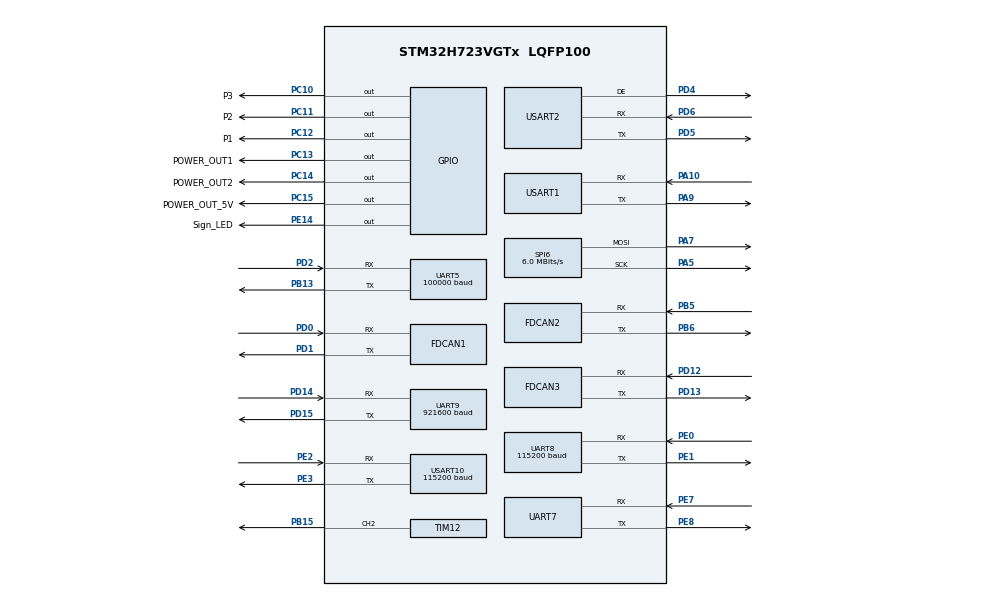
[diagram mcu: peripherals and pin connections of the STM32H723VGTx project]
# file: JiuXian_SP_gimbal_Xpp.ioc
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Bdma.Request0=SPI6_TX
Bdma.RequestsNb=1
Bdma.SPI6_TX.0.Direction=DMA_MEMORY_TO_PERIPH
Bdma.SPI6_TX.0.EventEnable=DISABLE
Bdma.SPI6_TX.0.Instance=BDMA_Channel0
Bdma.SPI6_TX.0.MemDataAlignment=DMA_MDATAALIGN_BYTE
Bdma.SPI6_TX.0.MemInc=DMA_MINC_ENABLE
Bdma.SPI6_TX.0.Mode=DMA_NORMAL
Bdma.SPI6_TX.0.PeriphDataAlignment=DMA_PDATAALIGN_BYTE
Bdma.SPI6_TX.0.PeriphInc=DMA_PINC_DISABLE
Bdma.SPI6_TX.0.Polarity=HAL_DMAMUX_REQ_GEN_RISING
Bdma.SPI6_TX.0.Priority=DMA_PRIORITY_LOW
Bdma.SPI6_TX.0.RequestNumber=1
Bdma.SPI6_TX.0.SignalID=NONE
Bdma.SPI6_TX.0.SyncEnable=DISABLE
Bdma.SPI6_TX.0.SyncPolarity=HAL_DMAMUX_SYNC_NO_EVENT
Bdma.SPI6_TX.0.SyncRequestNumber=1
Bdma.SPI6_TX.0.SyncSignalID=NONE
Dma.Request0=UART8_RX
Dma.Request1=UART8_TX
Dma.Request10=USART2_TX
Dma.Request11=USART10_RX
Dma.Request12=USART10_TX
Dma.Request2=UART9_RX
Dma.Request3=UART9_TX
Dma.Request4=USART1_RX
Dma.Request5=USART1_TX
Dma.Request6=UART7_RX
Dma.Request7=UART7_TX
Dma.Request8=UART5_RX
Dma.Request9=USART2_RX
Dma.UART5_RX.8.Direction=DMA_PERIPH_TO_MEMORY
Dma.UART5_RX.8.EventEnable=DISABLE
Dma.UART5_RX.8.FIFOMode=DMA_FIFOMODE_DISABLE
Dma.UART5_RX.8.Instance=DMA1_Stream0
Dma.UART5_RX.8.MemDataAlignment=DMA_MDATAALIGN_BYTE
Dma.UART5_RX.8.MemInc=DMA_MINC_ENABLE
Dma.UART5_RX.8.Mode=DMA_NORMAL
Dma.UART5_RX.8.PeriphDataAlignment=DMA_PDATAALIGN_BYTE
Dma.UART5_RX.8.PeriphInc=DMA_PINC_DISABLE
Dma.UART5_RX.8.Polarity=HAL_DMAMUX_REQ_GEN_RISING
Dma.UART5_RX.8.Priority=DMA_PRIORITY_HIGH
Dma.UART5_RX.8.RequestNumber=1
Dma.UART5_RX.8.SignalID=NONE
Dma.UART5_RX.8.SyncEnable=DISABLE
Dma.UART5_RX.8.SyncPolarity=HAL_DMAMUX_SYNC_NO_EVENT
Dma.UART5_RX.8.SyncRequestNumber=1
Dma.UART5_RX.8.SyncSignalID=NONE
Dma.UART7_RX.6.Direction=DMA_PERIPH_TO_MEMORY
Dma.UART7_RX.6.EventEnable=DISABLE
Dma.UART7_RX.6.FIFOMode=DMA_FIFOMODE_DISABLE
Dma.UART7_RX.6.Instance=DMA1_Stream6
Dma.UART7_RX.6.MemDataAlignment=DMA_MDATAALIGN_BYTE
Dma.UART7_RX.6.MemInc=DMA_MINC_ENABLE
Dma.UART7_RX.6.Mode=DMA_NORMAL
Dma.UART7_RX.6.PeriphDataAlignment=DMA_PDATAALIGN_BYTE
Dma.UART7_RX.6.PeriphInc=DMA_PINC_DISABLE
Dma.UART7_RX.6.Polarity=HAL_DMAMUX_REQ_GEN_RISING
Dma.UART7_RX.6.Priority=DMA_PRIORITY_LOW
Dma.UART7_RX.6.RequestNumber=1
Dma.UART7_RX.6.SignalID=NONE
Dma.UART7_RX.6.SyncEnable=DISABLE
Dma.UART7_RX.6.SyncPolarity=HAL_DMAMUX_SYNC_NO_EVENT
Dma.UART7_RX.6.SyncRequestNumber=1
Dma.UART7_RX.6.SyncSignalID=NONE
Dma.UART7_TX.7.Direction=DMA_MEMORY_TO_PERIPH
Dma.UART7_TX.7.EventEnable=DISABLE
Dma.UART7_TX.7.FIFOMode=DMA_FIFOMODE_DISABLE
Dma.UART7_TX.7.Instance=DMA1_Stream7
Dma.UART7_TX.7.MemDataAlignment=DMA_MDATAALIGN_BYTE
Dma.UART7_TX.7.MemInc=DMA_MINC_ENABLE
Dma.UART7_TX.7.Mode=DMA_NORMAL
Dma.UART7_TX.7.PeriphDataAlignment=DMA_PDATAALIGN_BYTE
Dma.UART7_TX.7.PeriphInc=DMA_PINC_DISABLE
Dma.UART7_TX.7.Polarity=HAL_DMAMUX_REQ_GEN_RISING
Dma.UART7_TX.7.Priority=DMA_PRIORITY_LOW
Dma.UART7_TX.7.RequestNumber=1
Dma.UART7_TX.7.SignalID=NONE
Dma.UART7_TX.7.SyncEnable=DISABLE
Dma.UART7_TX.7.SyncPolarity=HAL_DMAMUX_SYNC_NO_EVENT
Dma.UART7_TX.7.SyncRequestNumber=1
Dma.UART7_TX.7.SyncSignalID=NONE
Dma.UART8_RX.0.Direction=DMA_PERIPH_TO_MEMORY
Dma.UART8_RX.0.EventEnable=DISABLE
Dma.UART8_RX.0.FIFOMode=DMA_FIFOMODE_DISABLE
Dma.UART8_RX.0.Instance=DMA2_Stream0
Dma.UART8_RX.0.MemDataAlignment=DMA_MDATAALIGN_BYTE
Dma.UART8_RX.0.MemInc=DMA_MINC_ENABLE
Dma.UART8_RX.0.Mode=DMA_NORMAL
Dma.UART8_RX.0.PeriphDataAlignment=DMA_PDATAALIGN_BYTE
Dma.UART8_RX.0.PeriphInc=DMA_PINC_DISABLE
Dma.UART8_RX.0.Polarity=HAL_DMAMUX_REQ_GEN_RISING
Dma.UART8_RX.0.Priority=DMA_PRIORITY_LOW
Dma.UART8_RX.0.RequestNumber=1
Dma.UART8_RX.0.SignalID=NONE
Dma.UART8_RX.0.SyncEnable=DISABLE
Dma.UART8_RX.0.SyncPolarity=HAL_DMAMUX_SYNC_NO_EVENT
Dma.UART8_RX.0.SyncRequestNumber=1
Dma.UART8_RX.0.SyncSignalID=NONE
Dma.UART8_TX.1.Direction=DMA_MEMORY_TO_PERIPH
Dma.UART8_TX.1.EventEnable=DISABLE
Dma.UART8_TX.1.FIFOMode=DMA_FIFOMODE_DISABLE
Dma.UART8_TX.1.Instance=DMA1_Stream1
Dma.UART8_TX.1.MemDataAlignment=DMA_MDATAALIGN_BYTE
Dma.UART8_TX.1.MemInc=DMA_MINC_ENABLE
Dma.UART8_TX.1.Mode=DMA_NORMAL
Dma.UART8_TX.1.PeriphDataAlignment=DMA_PDATAALIGN_BYTE
Dma.UART8_TX.1.PeriphInc=DMA_PINC_DISABLE
Dma.UART8_TX.1.Polarity=HAL_DMAMUX_REQ_GEN_RISING
Dma.UART8_TX.1.Priority=DMA_PRIORITY_LOW
Dma.UART8_TX.1.RequestNumber=1
Dma.UART8_TX.1.SignalID=NONE
Dma.UART8_TX.1.SyncEnable=DISABLE
Dma.UART8_TX.1.SyncPolarity=HAL_DMAMUX_SYNC_NO_EVENT
Dma.UART8_TX.1.SyncRequestNumber=1
Dma.UART8_TX.1.SyncSignalID=NONE
Dma.UART9_RX.2.Direction=DMA_PERIPH_TO_MEMORY
Dma.UART9_RX.2.EventEnable=DISABLE
Dma.UART9_RX.2.FIFOMode=DMA_FIFOMODE_DISABLE
Dma.UART9_RX.2.Instance=DMA1_Stream2
Dma.UART9_RX.2.MemDataAlignment=DMA_MDATAALIGN_BYTE
Dma.UART9_RX.2.MemInc=DMA_MINC_ENABLE
Dma.UART9_RX.2.Mode=DMA_NORMAL
Dma.UART9_RX.2.PeriphDataAlignment=DMA_PDATAALIGN_BYTE
Dma.UART9_RX.2.PeriphInc=DMA_PINC_DISABLE
Dma.UART9_RX.2.Polarity=HAL_DMAMUX_REQ_GEN_RISING
Dma.UART9_RX.2.Priority=DMA_PRIORITY_LOW
Dma.UART9_RX.2.RequestNumber=1
Dma.UART9_RX.2.SignalID=NONE
Dma.UART9_RX.2.SyncEnable=DISABLE
Dma.UART9_RX.2.SyncPolarity=HAL_DMAMUX_SYNC_NO_EVENT
Dma.UART9_RX.2.SyncRequestNumber=1
Dma.UART9_RX.2.SyncSignalID=NONE
Dma.UART9_TX.3.Direction=DMA_MEMORY_TO_PERIPH
Dma.UART9_TX.3.EventEnable=DISABLE
Dma.UART9_TX.3.FIFOMode=DMA_FIFOMODE_DISABLE
Dma.UART9_TX.3.Instance=DMA1_Stream3
Dma.UART9_TX.3.MemDataAlignment=DMA_MDATAALIGN_BYTE
Dma.UART9_TX.3.MemInc=DMA_MINC_ENABLE
Dma.UART9_TX.3.Mode=DMA_NORMAL
Dma.UART9_TX.3.PeriphDataAlignment=DMA_PDATAALIGN_BYTE
Dma.UART9_TX.3.PeriphInc=DMA_PINC_DISABLE
Dma.UART9_TX.3.Polarity=HAL_DMAMUX_REQ_GEN_RISING
Dma.UART9_TX.3.Priority=DMA_PRIORITY_LOW
Dma.UART9_TX.3.RequestNumber=1
Dma.UART9_TX.3.SignalID=NONE
Dma.UART9_TX.3.SyncEnable=DISABLE
Dma.UART9_TX.3.SyncPolarity=HAL_DMAMUX_SYNC_NO_EVENT
Dma.UART9_TX.3.SyncRequestNumber=1
Dma.UART9_TX.3.SyncSignalID=NONE
Dma.USART10_RX.11.Direction=DMA_PERIPH_TO_MEMORY
Dma.USART10_RX.11.EventEnable=DISABLE
Dma.USART10_RX.11.FIFOMode=DMA_FIFOMODE_DISABLE
Dma.USART10_RX.11.Instance=DMA2_Stream3
Dma.USART10_RX.11.MemDataAlignment=DMA_MDATAALIGN_BYTE
Dma.USART10_RX.11.MemInc=DMA_MINC_ENABLE
Dma.USART10_RX.11.Mode=DMA_NORMAL
Dma.USART10_RX.11.PeriphDataAlignment=DMA_PDATAALIGN_BYTE
Dma.USART10_RX.11.PeriphInc=DMA_PINC_DISABLE
Dma.USART10_RX.11.Polarity=HAL_DMAMUX_REQ_GEN_RISING
Dma.USART10_RX.11.Priority=DMA_PRIORITY_LOW
Dma.USART10_RX.11.RequestNumber=1
Dma.USART10_RX.11.SignalID=NONE
Dma.USART10_RX.11.SyncEnable=DISABLE
Dma.USART10_RX.11.SyncPolarity=HAL_DMAMUX_SYNC_NO_EVENT
Dma.USART10_RX.11.SyncRequestNumber=1
Dma.USART10_RX.11.SyncSignalID=NONE
Dma.USART10_TX.12.Direction=DMA_MEMORY_TO_PERIPH
Dma.USART10_TX.12.EventEnable=DISABLE
Dma.USART10_TX.12.FIFOMode=DMA_FIFOMODE_DISABLE
Dma.USART10_TX.12.Instance=DMA2_Stream4
Dma.USART10_TX.12.MemDataAlignment=DMA_MDATAALIGN_BYTE
Dma.USART10_TX.12.MemInc=DMA_MINC_ENABLE
Dma.USART10_TX.12.Mode=DMA_NORMAL
Dma.USART10_TX.12.PeriphDataAlignment=DMA_PDATAALIGN_BYTE
Dma.USART10_TX.12.PeriphInc=DMA_PINC_DISABLE
Dma.USART10_TX.12.Polarity=HAL_DMAMUX_REQ_GEN_RISING
Dma.USART10_TX.12.Priority=DMA_PRIORITY_LOW
Dma.USART10_TX.12.RequestNumber=1
Dma.USART10_TX.12.SignalID=NONE
Dma.USART10_TX.12.SyncEnable=DISABLE
Dma.USART10_TX.12.SyncPolarity=HAL_DMAMUX_SYNC_NO_EVENT
Dma.USART10_TX.12.SyncRequestNumber=1
Dma.USART10_TX.12.SyncSignalID=NONE
Dma.USART1_RX.4.Direction=DMA_PERIPH_TO_MEMORY
Dma.USART1_RX.4.EventEnable=DISABLE
Dma.USART1_RX.4.FIFOMode=DMA_FIFOMODE_DISABLE
Dma.USART1_RX.4.Instance=DMA1_Stream4
Dma.USART1_RX.4.MemDataAlignment=DMA_MDATAALIGN_BYTE
Dma.USART1_RX.4.MemInc=DMA_MINC_ENABLE
Dma.USART1_RX.4.Mode=DMA_NORMAL
Dma.USART1_RX.4.PeriphDataAlignment=DMA_PDATAALIGN_BYTE
Dma.USART1_RX.4.PeriphInc=DMA_PINC_DISABLE
Dma.USART1_RX.4.Polarity=HAL_DMAMUX_REQ_GEN_RISING
Dma.USART1_RX.4.Priority=DMA_PRIORITY_LOW
Dma.USART1_RX.4.RequestNumber=1
Dma.USART1_RX.4.SignalID=NONE
Dma.USART1_RX.4.SyncEnable=DISABLE
Dma.USART1_RX.4.SyncPolarity=HAL_DMAMUX_SYNC_NO_EVENT
Dma.USART1_RX.4.SyncRequestNumber=1
Dma.USART1_RX.4.SyncSignalID=NONE
Dma.USART1_TX.5.Direction=DMA_MEMORY_TO_PERIPH
Dma.USART1_TX.5.EventEnable=DISABLE
Dma.USART1_TX.5.FIFOMode=DMA_FIFOMODE_DISABLE
Dma.USART1_TX.5.Instance=DMA1_Stream5
Dma.USART1_TX.5.MemDataAlignment=DMA_MDATAALIGN_BYTE
Dma.USART1_TX.5.MemInc=DMA_MINC_ENABLE
Dma.USART1_TX.5.Mode=DMA_NORMAL
Dma.USART1_TX.5.PeriphDataAlignment=DMA_PDATAALIGN_BYTE
Dma.USART1_TX.5.PeriphInc=DMA_PINC_DISABLE
Dma.USART1_TX.5.Polarity=HAL_DMAMUX_REQ_GEN_RISING
Dma.USART1_TX.5.Priority=DMA_PRIORITY_LOW
Dma.USART1_TX.5.RequestNumber=1
Dma.USART1_TX.5.SignalID=NONE
Dma.USART1_TX.5.SyncEnable=DISABLE
Dma.USART1_TX.5.SyncPolarity=HAL_DMAMUX_SYNC_NO_EVENT
Dma.USART1_TX.5.SyncRequestNumber=1
Dma.USART1_TX.5.SyncSignalID=NONE
Dma.USART2_RX.9.Direction=DMA_PERIPH_TO_MEMORY
Dma.USART2_RX.9.EventEnable=DISABLE
Dma.USART2_RX.9.FIFOMode=DMA_FIFOMODE_DISABLE
Dma.USART2_RX.9.Instance=DMA2_Stream1
Dma.USART2_RX.9.MemDataAlignment=DMA_MDATAALIGN_BYTE
Dma.USART2_RX.9.MemInc=DMA_MINC_ENABLE
Dma.USART2_RX.9.Mode=DMA_NORMAL
Dma.USART2_RX.9.PeriphDataAlignment=DMA_PDATAALIGN_BYTE
Dma.USART2_RX.9.PeriphInc=DMA_PINC_DISABLE
Dma.USART2_RX.9.Polarity=HAL_DMAMUX_REQ_GEN_RISING
Dma.USART2_RX.9.Priority=DMA_PRIORITY_LOW
Dma.USART2_RX.9.RequestNumber=1
Dma.USART2_RX.9.SignalID=NONE
Dma.USART2_RX.9.SyncEnable=DISABLE
Dma.USART2_RX.9.SyncPolarity=HAL_DMAMUX_SYNC_NO_EVENT
Dma.USART2_RX.9.SyncRequestNumber=1
Dma.USART2_RX.9.SyncSignalID=NONE
Dma.USART2_TX.10.Direction=DMA_MEMORY_TO_PERIPH
Dma.USART2_TX.10.EventEnable=DISABLE
Dma.USART2_TX.10.FIFOMode=DMA_FIFOMODE_DISABLE
Dma.USART2_TX.10.Instance=DMA2_Stream2
Dma.USART2_TX.10.MemDataAlignment=DMA_MDATAALIGN_BYTE
Dma.USART2_TX.10.MemInc=DMA_MINC_ENABLE
Dma.USART2_TX.10.Mode=DMA_NORMAL
Dma.USART2_TX.10.PeriphDataAlignment=DMA_PDATAALIGN_BYTE
Dma.USART2_TX.10.PeriphInc=DMA_PINC_DISABLE
Dma.USART2_TX.10.Polarity=HAL_DMAMUX_REQ_GEN_RISING
Dma.USART2_TX.10.Priority=DMA_PRIORITY_LOW
Dma.USART2_TX.10.RequestNumber=1
Dma.USART2_TX.10.SignalID=NONE
Dma.USART2_TX.10.SyncEnable=DISABLE
Dma.USART2_TX.10.SyncPolarity=HAL_DMAMUX_SYNC_NO_EVENT
Dma.USART2_TX.10.SyncRequestNumber=1
Dma.USART2_TX.10.SyncSignalID=NONE
FDCAN1.AutoRetransmission=ENABLE
FDCAN1.CalculateBaudRateNominal=1000000
FDCAN1.CalculateTimeBitNominal=1000
FDCAN1.CalculateTimeQuantumNominal=25.0
FDCAN1.DataPrescaler=3
FDCAN1.DataSyncJumpWidth=10
FDCAN1.DataTimeSeg1=29
FDCAN1.DataTimeSeg2=10
FDCAN1.NominalPrescaler=3
FDCAN1.NominalSyncJumpWidth=10
FDCAN1.NominalTimeSeg1=29
FDCAN1.NominalTimeSeg2=10
FDCAN1.RxFifo0ElmtsNbr=16
FDCAN1.StdFiltersNbr=1
FDCAN1.TxFifoQueueElmtsNbr=8
FDCAN2.AutoRetransmission=ENABLE
FDCAN2.CalculateBaudRateNominal=1000000
FDCAN2.CalculateTimeBitNominal=1000
FDCAN2.CalculateTimeQuantumNominal=25.0
FDCAN2.DataPrescaler=3
FDCAN2.DataSyncJumpWidth=2
FDCAN2.DataTimeSeg1=5
FDCAN2.DataTimeSeg2=2
FDCAN2.FrameFormat=FDCAN_FRAME_FD_BRS
FDCAN2.MessageRAMOffset=853
FDCAN2.Mode=FDCAN_MODE_NORMAL
FDCAN2.NominalPrescaler=3
FDCAN2.NominalSyncJumpWidth=10
FDCAN2.NominalTimeSeg1=29
FDCAN2.NominalTimeSeg2=10
FDCAN2.RxFifo0ElmtSize=FDCAN_DATA_BYTES_64
FDCAN2.RxFifo0ElmtsNbr=8
FDCAN2.StdFiltersNbr=1
FDCAN2.TxElmtSize=FDCAN_DATA_BYTES_64
FDCAN2.TxFifoQueueElmtsNbr=8
FDCAN3.AutoRetransmission=ENABLE
FDCAN3.CalculateBaudRateNominal=1000000
FDCAN3.CalculateTimeBitNominal=1000
FDCAN3.CalculateTimeQuantumNominal=25.0
FDCAN3.DataPrescaler=3
FDCAN3.DataSyncJumpWidth=10
FDCAN3.DataTimeSeg1=29
FDCAN3.DataTimeSeg2=10
FDCAN3.MessageRAMOffset=1706
FDCAN3.NominalPrescaler=3
FDCAN3.NominalSyncJumpWidth=10
FDCAN3.NominalTimeSeg1=29
FDCAN3.NominalTimeSeg2=10
FDCAN3.RxFifo0ElmtsNbr=16
FDCAN3.StdFiltersNbr=1
FDCAN3.TxFifoQueueElmtsNbr=8
FREERTOS.Tasks01=defaultTask,49,128,InitNcheckTask,As weak,NULL,Dynamic,NULL,NULL;myTask02,49,256,FC_node,As weak,NULL,Dynamic,NULL,NULL;myTask03,49,256,Interaction_node,As weak,NULL,Dynamic,NULL,NULL;myTask04,49,128,Buzzer_node,As weak,NULL,Dynamic,NULL,NULL;myTask05,49,256,RoboMaster_Standard_Link_node,As weak,NULL,Dynamic,NULL,NULL;myTask06,49,256,RoboMaster_VTM_Link_node,As weak,NULL,Dynamic,NULL,NULL;myTask07,49,256,MiniPC_node,As weak,NULL,Dynamic,NULL,NULL;myTask08,49,128,Remote_node,As weak,NULL,Dynamic,NULL,NULL;myTask09,49,256,Gimbal_Ctrl_node,As weak,NULL,Dynamic,NULL,NULL;myTask10,49,256,IMU_node,As weak,NULL,Dynamic,NULL,NULL
FREERTOS.configENABLE_FPU=1
Mcu.Family=STM32H7
Mcu.Name=STM32H723VGTx
Mcu.Package=LQFP100
NVIC.BDMA_Channel0_IRQn=true\:5\:0\:false\:false\:true\:true\:false\:true\:true
NVIC.DMA1_Stream0_IRQn=true\:5\:0\:false\:false\:true\:true\:false\:true\:true
NVIC.DMA1_Stream1_IRQn=true\:5\:0\:false\:false\:true\:true\:false\:true\:true
NVIC.DMA1_Stream2_IRQn=true\:5\:0\:false\:false\:true\:true\:false\:true\:true
NVIC.DMA1_Stream3_IRQn=true\:5\:0\:false\:false\:true\:true\:false\:true\:true
NVIC.DMA1_Stream4_IRQn=true\:5\:0\:false\:false\:true\:true\:false\:true\:true
NVIC.DMA1_Stream5_IRQn=true\:5\:0\:false\:false\:true\:true\:false\:true\:true
NVIC.DMA1_Stream6_IRQn=true\:5\:0\:false\:false\:true\:true\:false\:true\:true
NVIC.DMA1_Stream7_IRQn=true\:5\:0\:false\:false\:true\:true\:false\:true\:true
NVIC.DMA2_Stream0_IRQn=true\:5\:0\:false\:false\:true\:true\:false\:true\:true
NVIC.DMA2_Stream1_IRQn=true\:5\:0\:false\:false\:true\:true\:false\:true\:true
NVIC.DMA2_Stream2_IRQn=true\:5\:0\:false\:false\:true\:true\:false\:true\:true
NVIC.DMA2_Stream3_IRQn=true\:5\:0\:false\:false\:true\:true\:false\:true\:true
NVIC.DMA2_Stream4_IRQn=true\:5\:0\:false\:false\:true\:true\:false\:true\:true
NVIC.FDCAN1_IT0_IRQn=true\:5\:0\:false\:false\:true\:true\:true\:true\:true
NVIC.FDCAN1_IT1_IRQn=true\:5\:0\:false\:false\:true\:true\:true\:true\:true
NVIC.FDCAN2_IT0_IRQn=true\:5\:0\:false\:false\:true\:true\:true\:true\:true
NVIC.FDCAN2_IT1_IRQn=true\:5\:0\:false\:false\:true\:true\:true\:true\:true
NVIC.FDCAN3_IT0_IRQn=true\:5\:0\:false\:false\:true\:true\:true\:true\:true
NVIC.FDCAN3_IT1_IRQn=true\:5\:0\:false\:false\:true\:true\:true\:true\:true
NVIC.PriorityGroup=NVIC_PRIORITYGROUP_4
NVIC.SPI6_IRQn=true\:5\:0\:false\:false\:true\:true\:false\:true\:true
NVIC.TIM1_UP_IRQn=true\:5\:0\:false\:false\:true\:true\:true\:true\:true
NVIC.TIM2_IRQn=true\:15\:0\:false\:false\:true\:false\:false\:true\:true
NVIC.TIM3_IRQn=true\:5\:0\:false\:false\:true\:true\:true\:true\:true
NVIC.TimeBase=TIM2_IRQn
NVIC.TimeBaseIP=TIM2
NVIC.UART5_IRQn=true\:5\:0\:false\:false\:true\:true\:true\:true\:true
NVIC.UART7_IRQn=true\:5\:0\:false\:false\:true\:true\:true\:true\:true
NVIC.UART8_IRQn=true\:5\:0\:false\:false\:true\:true\:true\:true\:true
NVIC.UART9_IRQn=true\:5\:0\:false\:false\:true\:true\:true\:true\:true
NVIC.USART10_IRQn=true\:5\:0\:false\:false\:true\:true\:true\:true\:true
NVIC.USART1_IRQn=true\:5\:0\:false\:false\:true\:true\:true\:true\:true
NVIC.USART2_IRQn=true\:5\:0\:false\:false\:true\:true\:true\:true\:true
PA10.Mode=Asynchronous
PA10.Signal=USART1_RX
PA13(JTMS/SWDIO).Mode=Serial_Wire
PA13(JTMS/SWDIO).Signal=DEBUG_JTMS-SWDIO
PA14(JTCK/SWCLK).Mode=Serial_Wire
PA14(JTCK/SWCLK).Signal=DEBUG_JTCK-SWCLK
PA5.Mode=TX_Only_Simplex_Unidirect_Master
PA5.Signal=SPI6_SCK
PA7.Mode=TX_Only_Simplex_Unidirect_Master
PA7.Signal=SPI6_MOSI
PA9.Mode=Asynchronous
PA9.Signal=USART1_TX
PB13.Mode=Asynchronous
PB13.Signal=UART5_TX
PB15.Signal=S_TIM12_CH2
PB5.Mode=FDCAN_Activate
PB5.Signal=FDCAN2_RX
PB6.Mode=FDCAN_Activate
PB6.Signal=FDCAN2_TX
PC10.GPIO_Label=P3
PC10.Signal=GPIO_Output
PC11.GPIO_Label=P2
PC11.Signal=GPIO_Output
PC12.GPIO_Label=P1
PC12.Signal=GPIO_Output
PC13.GPIO_Label=POWER_OUT1
PC13.Signal=GPIO_Output
PC14-OSC32_IN.GPIO_Label=POWER_OUT2
PC14-OSC32_IN.Signal=GPIO_Output
PC15-OSC32_OUT.GPIO_Label=POWER_OUT_5V
PC15-OSC32_OUT.Signal=GPIO_Output
PD0.Mode=FDCAN_Activate
PD0.Signal=FDCAN1_RX
PD1.Mode=FDCAN_Activate
PD1.Signal=FDCAN1_TX
PD12.Mode=FDCAN_Activate
PD12.Signal=FDCAN3_RX
PD13.Mode=FDCAN_Activate
PD13.Signal=FDCAN3_TX
PD14.Mode=Asynchronous
PD14.Signal=UART9_RX
PD15.Mode=Asynchronous
PD15.Signal=UART9_TX
PD2.Mode=Asynchronous
PD2.Signal=UART5_RX
PD4.Mode=Hardware Flow Control (RS485)
PD4.Signal=USART2_DE
PD5.Mode=Asynchronous
PD5.Signal=USART2_TX
PD6.Mode=Asynchronous
PD6.Signal=USART2_RX
PE0.Mode=Asynchronous
PE0.Signal=UART8_RX
PE1.Mode=Asynchronous
PE1.Signal=UART8_TX
PE14.GPIO_Label=Sign_LED
PE14.Signal=GPIO_Output
PE2.Mode=Asynchronous
PE2.Signal=USART10_RX
PE3.Mode=Asynchronous
PE3.Signal=USART10_TX
PE7.Mode=Asynchronous
PE7.Signal=UART7_RX
PE8.Mode=Asynchronous
PE8.Signal=UART7_TX
PH0-OSC_IN.Mode=HSE-External-Oscillator
PH0-OSC_IN.Signal=RCC_OSC_IN
PH1-OSC_OUT.Mode=HSE-External-Oscillator
PH1-OSC_OUT.Signal=RCC_OSC_OUT
ProjectManager.HeapSize=0x2000
ProjectManager.StackSize=0x4000
ProjectManager.TargetToolchain=CMake
RCC.ADCFreq_Value=48375000
RCC.APB1Freq_Value=120000000
RCC.APB2Freq_Value=120000000
RCC.APB3Freq_Value=120000000
RCC.APB4Freq_Value=120000000
RCC.CortexFreq_Value=480000000
RCC.D1PPRE=RCC_APB3_DIV2
RCC.D2PPRE1=RCC_APB1_DIV2
RCC.D2PPRE2=RCC_APB2_DIV2
RCC.D3PPRE=RCC_APB4_DIV2
RCC.DIVM1=2
RCC.DIVN1=40
RCC.DIVP1=1
RCC.DIVQ1=4
RCC.HCLKFreq_Value=240000000
RCC.HPRE=RCC_HCLK_DIV2
RCC.HSE_VALUE=24000000
RCC.PLLSourceVirtual=RCC_PLLSOURCE_HSE
RCC.SPI6CLockSelection=RCC_SPI6CLKSOURCE_HSE
RCC.SYSCLKFreq_VALUE=480000000
RCC.SYSCLKSource=RCC_SYSCLKSOURCE_PLLCLK
RCC.USBFreq_Value=120000000
SH.S_TIM12_CH2.0=TIM12_CH2,PWM Generation2 CH2
SPI6.BaudRatePrescaler=SPI_BAUDRATEPRESCALER_4
SPI6.CLKPhase=SPI_PHASE_2EDGE
SPI6.CalculateBaudRate=6.0 MBits/s
SPI6.DataSize=SPI_DATASIZE_8BIT
SPI6.Direction=SPI_DIRECTION_2LINES_TXONLY
SPI6.Mode=SPI_MODE_MASTER
SPI6.VirtualType=VM_MASTER
STMicroelectronics.X-CUBE-ALGOBUILD.1.5.0.LibraryCcDSPOoLibraryJjDSPOoLibrary=true
TIM1.Period=999
TIM1.Prescaler=239
TIM12.Channel-PWM\ Generation2\ CH2=TIM_CHANNEL_2
TIM12.Period=1999
TIM12.Prescaler=23
TIM3.Period=999
TIM3.Prescaler=239
UART5.BaudRate=100000
UART5.Mode=MODE_TX_RX
UART5.Parity=PARITY_EVEN
UART5.StopBits=UART_STOPBITS_2
UART5.WordLength=WORDLENGTH_9B
UART8.BaudRate=115200
UART9.BaudRate=921600
USART1.VirtualMode-Asynchronous=VM_ASYNC
USART10.BaudRate=115200
USART10.VirtualMode=VM_ASYNC
USART2.OverSampling=UART_OVERSAMPLING_8
USART2.VirtualMode-Asynchronous=VM_ASYNC
USART2.VirtualMode-Hardware\ Flow\ Control\ (RS485)=VM_ASYNC
VP_FREERTOS_VS_CMSIS_V2.Mode=CMSIS_V2
VP_MEMORYMAP_VS_MEMORYMAP.Mode=CurAppReg
VP_STMicroelectronics.X-CUBE-ALGOBUILD_VS_DSPOoLibraryJjLibrary_1.5.0_1.5.0.Mode=DSPOoLibraryJjLibrary
VP_SYS_VS_tim2.Mode=TIM2
VP_TIM1_VS_ClockSourceINT.Mode=Internal
VP_TIM3_VS_ClockSourceINT.Mode=Internal
board=custom

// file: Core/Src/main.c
/* USER CODE BEGIN Header */
/**
  ******************************************************************************
  * @file           : main.c
  * @brief          : Main program body
  ******************************************************************************
  * @attention
  *
  * Copyright (c) 2026 STMicroelectronics.
  * All rights reserved.
  *
  * This software is licensed under terms that can be found in the LICENSE file
  * in the root directory of this software component.
  * If no LICENSE file comes with this software, it is provided AS-IS.
  *
  ******************************************************************************
  */
/* USER CODE END Header */
#include "main.h"
#include "FreeRTOS.h"
#include "cmsis_os2.h"
#include "bdma.h"
#include "dma.h"
#include "fdcan.h"
#include "spi.h"
#include "tim.h"
#include "usart.h"
#include "gpio.h"

/* USER CODE BEGIN Includes */
#include "../../IT/Inc/it.h"
/* USER CODE END Includes */

void SystemClock_Config(void);
void MX_FREERTOS_Init(void);

int main(void)
{

  /* MCU Configuration--------------------------------------------------------*/

  /* Reset of all peripherals, Initializes the Flash interface and the Systick. */
  HAL_Init();

  /* Configure the system clock */
  SystemClock_Config();

  /* Initialize all configured peripherals */
  MX_GPIO_Init();
  MX_BDMA_Init();
  MX_DMA_Init();
  MX_TIM1_Init();
  MX_SPI6_Init();
  MX_TIM3_Init();
  MX_FDCAN3_Init();
  MX_FDCAN2_Init();
  MX_TIM12_Init();
  MX_UART8_Init();
  MX_UART9_Init();
  MX_USART1_UART_Init();
  MX_UART7_Init();
  MX_UART5_Init();
  MX_FDCAN1_Init();
  MX_USART2_UART_Init();
  MX_USART10_UART_Init();
  /* USER CODE BEGIN 2 */
  HAL_TIM_Base_Start_IT(&htim1);
  HAL_TIM_Base_Start_IT(&htim3);
  HAL_TIM_PWM_Start(&htim12, TIM_CHANNEL_2);
  /* USER CODE END 2 */

  /* Init scheduler */
  osKernelInitialize();  /* Call init function for freertos objects (in cmsis_os2.c) */
  MX_FREERTOS_Init();

  /* Start scheduler */
  osKernelStart();

  /* We should never get here as control is now taken by the scheduler */

  /* Infinite loop */
  while (1)
  {

  }
}

void SystemClock_Config(void)
{
  RCC_OscInitTypeDef RCC_OscInitStruct = {0};
  RCC_ClkInitTypeDef RCC_ClkInitStruct = {0};

  /** Supply configuration update enable
  */
  HAL_PWREx_ConfigSupply(PWR_LDO_SUPPLY);

  /** Configure the main internal regulator output voltage
  */
  __HAL_PWR_VOLTAGESCALING_CONFIG(PWR_REGULATOR_VOLTAGE_SCALE0);

  while(!__HAL_PWR_GET_FLAG(PWR_FLAG_VOSRDY)) {}

  /** Initializes the RCC Oscillators according to the specified parameters
  * in the RCC_OscInitTypeDef structure.
  */
  RCC_OscInitStruct.OscillatorType = RCC_OSCILLATORTYPE_HSE;
  RCC_OscInitStruct.HSEState = RCC_HSE_ON;
  RCC_OscInitStruct.PLL.PLLState = RCC_PLL_ON;
  RCC_OscInitStruct.PLL.PLLSource = RCC_PLLSOURCE_HSE;
  RCC_OscInitStruct.PLL.PLLM = 2;
  RCC_OscInitStruct.PLL.PLLN = 40;
  RCC_OscInitStruct.PLL.PLLP = 1;
  RCC_OscInitStruct.PLL.PLLQ = 4;
  RCC_OscInitStruct.PLL.PLLR = 2;
  RCC_OscInitStruct.PLL.PLLRGE = RCC_PLL1VCIRANGE_3;
  RCC_OscInitStruct.PLL.PLLVCOSEL = RCC_PLL1VCOWIDE;
  RCC_OscInitStruct.PLL.PLLFRACN = 0;
  if (HAL_RCC_OscConfig(&RCC_OscInitStruct) != HAL_OK)
  {
    Error_Handler();
  }

  /** Initializes the CPU, AHB and APB buses clocks
  */
  RCC_ClkInitStruct.ClockType = RCC_CLOCKTYPE_HCLK|RCC_CLOCKTYPE_SYSCLK
                              |RCC_CLOCKTYPE_PCLK1|RCC_CLOCKTYPE_PCLK2
                              |RCC_CLOCKTYPE_D3PCLK1|RCC_CLOCKTYPE_D1PCLK1;
  RCC_ClkInitStruct.SYSCLKSource = RCC_SYSCLKSOURCE_PLLCLK;
  RCC_ClkInitStruct.SYSCLKDivider = RCC_SYSCLK_DIV1;
  RCC_ClkInitStruct.AHBCLKDivider = RCC_HCLK_DIV2;
  RCC_ClkInitStruct.APB3CLKDivider = RCC_APB3_DIV2;
  RCC_ClkInitStruct.APB1CLKDivider = RCC_APB1_DIV2;
  RCC_ClkInitStruct.APB2CLKDivider = RCC_APB2_DIV2;
  RCC_ClkInitStruct.APB4CLKDivider = RCC_APB4_DIV2;

  if (HAL_RCC_ClockConfig(&RCC_ClkInitStruct, FLASH_LATENCY_3) != HAL_OK)
  {
    Error_Handler();
  }
}

void HAL_TIM_PeriodElapsedCallback(TIM_HandleTypeDef *htim)
{
  /* USER CODE BEGIN Callback 0 */
  if (htim->Instance == TIM1)
  {
    TIM1_Period_Callback();
  }
  if (htim->Instance == TIM3)
  {
    TIM3_State_Update_Callback();
  }
  /* USER CODE END Callback 0 */
  if (htim->Instance == TIM2)
  {
    HAL_IncTick();
  }
}

void Error_Handler(void)
{
  __disable_irq();
  while (1)
  {
  }
}

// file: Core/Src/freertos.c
/* USER CODE BEGIN Header */
/**
  ******************************************************************************
  * File Name          : freertos.c
  * Description        : Code for freertos applications
  ******************************************************************************
  * @attention
  *
  * Copyright (c) 2026 STMicroelectronics.
  * All rights reserved.
  *
  * This software is licensed under terms that can be found in the LICENSE file
  * in the root directory of this software component.
  * If no LICENSE file comes with this software, it is provided AS-IS.
  *
  ******************************************************************************
  */
/* USER CODE END Header */

#include "FreeRTOS.h"
#include "task.h"
#include "main.h"
#include "FreeRTOS.h"
#include "cmsis_os2.h"

/* Definitions for defaultTask */
osThreadId_t defaultTaskHandle;
const osThreadAttr_t defaultTask_attributes = {
  .name = "defaultTask",
  .stack_size = 128 * 4,
  .priority = (osPriority_t) osPriorityRealtime1,
};
/* Definitions for myTask02 */
osThreadId_t myTask02Handle;
const osThreadAttr_t myTask02_attributes = {
  .name = "myTask02",
  .stack_size = 256 * 4,
  .priority = (osPriority_t) osPriorityRealtime1,
};
/* Definitions for myTask03 */
osThreadId_t myTask03Handle;
const osThreadAttr_t myTask03_attributes = {
  .name = "myTask03",
  .stack_size = 256 * 4,
  .priority = (osPriority_t) osPriorityRealtime1,
};
/* Definitions for myTask04 */
osThreadId_t myTask04Handle;
const osThreadAttr_t myTask04_attributes = {
  .name = "myTask04",
  .stack_size = 128 * 4,
  .priority = (osPriority_t) osPriorityRealtime1,
};
/* Definitions for myTask05 */
osThreadId_t myTask05Handle;
const osThreadAttr_t myTask05_attributes = {
  .name = "myTask05",
  .stack_size = 256 * 4,
  .priority = (osPriority_t) osPriorityRealtime1,
};
/* Definitions for myTask06 */
osThreadId_t myTask06Handle;
const osThreadAttr_t myTask06_attributes = {
  .name = "myTask06",
  .stack_size = 256 * 4,
  .priority = (osPriority_t) osPriorityRealtime1,
};
/* Definitions for myTask07 */
osThreadId_t myTask07Handle;
const osThreadAttr_t myTask07_attributes = {
  .name = "myTask07",
  .stack_size = 256 * 4,
  .priority = (osPriority_t) osPriorityRealtime1,
};
/* Definitions for myTask08 */
osThreadId_t myTask08Handle;
const osThreadAttr_t myTask08_attributes = {
  .name = "myTask08",
  .stack_size = 128 * 4,
  .priority = (osPriority_t) osPriorityRealtime1,
};
/* Definitions for myTask09 */
osThreadId_t myTask09Handle;
const osThreadAttr_t myTask09_attributes = {
  .name = "myTask09",
  .stack_size = 256 * 4,
  .priority = (osPriority_t) osPriorityRealtime1,
};
/* Definitions for myTask10 */
osThreadId_t myTask10Handle;
const osThreadAttr_t myTask10_attributes = {
  .name = "myTask10",
  .stack_size = 256 * 4,
  .priority = (osPriority_t) osPriorityRealtime1,
};

void InitNcheckTask(void *argument);
void FC_node(void *argument);
void Interaction_node(void *argument);
void Buzzer_node(void *argument);
void RoboMaster_Standard_Link_node(void *argument);
void RoboMaster_VTM_Link_node(void *argument);
void MiniPC_node(void *argument);
void Remote_node(void *argument);
void Gimbal_Ctrl_node(void *argument);
void IMU_node(void *argument);

void MX_FREERTOS_Init(void); /* (MISRA C 2004 rule 8.1) */

void MX_FREERTOS_Init(void) {

  /* Create the thread(s) */
  /* creation of defaultTask */
  defaultTaskHandle = osThreadNew(InitNcheckTask, NULL, &defaultTask_attributes);

  /* creation of myTask02 */
  myTask02Handle = osThreadNew(FC_node, NULL, &myTask02_attributes);

  /* creation of myTask03 */
  myTask03Handle = osThreadNew(Interaction_node, NULL, &myTask03_attributes);

  /* creation of myTask04 */
  myTask04Handle = osThreadNew(Buzzer_node, NULL, &myTask04_attributes);

  /* creation of myTask05 */
  myTask05Handle = osThreadNew(RoboMaster_Standard_Link_node, NULL, &myTask05_attributes);

  /* creation of myTask06 */
  myTask06Handle = osThreadNew(RoboMaster_VTM_Link_node, NULL, &myTask06_attributes);

  /* creation of myTask07 */
  myTask07Handle = osThreadNew(MiniPC_node, NULL, &myTask07_attributes);

  /* creation of myTask08 */
  myTask08Handle = osThreadNew(Remote_node, NULL, &myTask08_attributes);

  /* creation of myTask09 */
  myTask09Handle = osThreadNew(Gimbal_Ctrl_node, NULL, &myTask09_attributes);

  /* creation of myTask10 */
  myTask10Handle = osThreadNew(IMU_node, NULL, &myTask10_attributes);

}

__weak void InitNcheckTask(void *argument)
{
  for(;;)
  {
    osDelay(1);
  }
}

__weak void FC_node(void *argument)
{
  for(;;)
  {
    osDelay(1);
  }
}

__weak void Interaction_node(void *argument)
{
  for(;;)
  {
    osDelay(1);
  }
}

__weak void Buzzer_node(void *argument)
{
  for(;;)
  {
    osDelay(1);
  }
}

__weak void RoboMaster_Standard_Link_node(void *argument)
{
  for(;;)
  {
    osDelay(1);
  }
}

__weak void RoboMaster_VTM_Link_node(void *argument)
{
  for(;;)
  {
    osDelay(1);
  }
}

__weak void MiniPC_node(void *argument)
{
  for(;;)
  {
    osDelay(1);
  }
}

__weak void Remote_node(void *argument)
{
  for(;;)
  {
    osDelay(1);
  }
}

__weak void Gimbal_Ctrl_node(void *argument)
{
  for(;;)
  {
    osDelay(1);
  }
}

__weak void IMU_node(void *argument)
{
  for(;;)
  {
    osDelay(1);
  }
}
